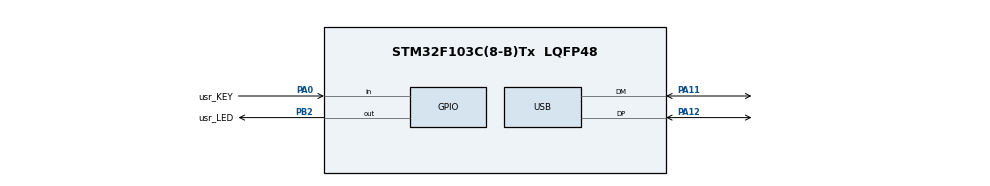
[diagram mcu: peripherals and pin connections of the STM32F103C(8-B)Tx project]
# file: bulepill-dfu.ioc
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Mcu.Family=STM32F1
Mcu.Name=STM32F103C(8-B)Tx
Mcu.Package=LQFP48
NVIC.PriorityGroup=NVIC_PRIORITYGROUP_4
NVIC.USB_LP_CAN1_RX0_IRQn=true\:0\:0\:false\:false\:true\:false\:true\:true
PA0-WKUP.GPIO_Label=usr_KEY
PA0-WKUP.GPIO_PuPd=GPIO_PULLDOWN
PA0-WKUP.Signal=GPIO_Input
PA11.Mode=Device
PA11.Signal=USB_DM
PA12.Mode=Device
PA12.Signal=USB_DP
PA13.Mode=Serial_Wire
PA13.Signal=SYS_JTMS-SWDIO
PA14.Mode=Serial_Wire
PA14.Signal=SYS_JTCK-SWCLK
PB2.GPIO_Label=usr_LED
PB2.Signal=GPIO_Output
PC14-OSC32_IN.Mode=LSE-External-Oscillator
PC14-OSC32_IN.Signal=RCC_OSC32_IN
PC15-OSC32_OUT.Mode=LSE-External-Oscillator
PC15-OSC32_OUT.Signal=RCC_OSC32_OUT
PD0-OSC_IN.Mode=HSE-External-Oscillator
PD0-OSC_IN.Signal=RCC_OSC_IN
PD1-OSC_OUT.Mode=HSE-External-Oscillator
PD1-OSC_OUT.Signal=RCC_OSC_OUT
ProjectManager.HeapSize=0x800
ProjectManager.StackSize=0x800
ProjectManager.TargetToolchain=Makefile
RCC.AHBFreq_Value=72000000
RCC.APB1CLKDivider=RCC_HCLK_DIV2
RCC.APB1Freq_Value=36000000
RCC.APB1TimFreq_Value=72000000
RCC.APB2Freq_Value=72000000
RCC.APB2TimFreq_Value=72000000
RCC.HCLKFreq_Value=72000000
RCC.HSICalibrationValue=8
RCC.PLLMUL=RCC_PLL_MUL9
RCC.SYSCLKFreq_VALUE=72000000
RCC.SYSCLKSource=RCC_SYSCLKSOURCE_PLLCLK
RCC.USBFreq_Value=48000000
RCC.USBPrescaler=RCC_USBCLKSOURCE_PLL_DIV1_5
USB_DEVICE.CLASS_NAME_FS=DFU
USB_DEVICE.USBD_DFU_APP_DEFAULT_ADD=0x08005800
USB_DEVICE.USBD_DFU_MEDIA=@Internal Flash   /0x08000000/22*001Ka,42*001Kg
USB_DEVICE.VirtualMode=Dfu
USB_DEVICE.VirtualModeFS=Dfu_FS
VP_USB_DEVICE_VS_USB_DEVICE_DFU_FS.Mode=DFU_FS
board=custom

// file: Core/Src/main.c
/* USER CODE BEGIN Header */
/**
  ******************************************************************************
  * @file           : main.c
  * @brief          : Main program body
  ******************************************************************************
  * @attention
  *
  * Copyright (c) 2024 STMicroelectronics.
  * All rights reserved.
  *
  * This software is licensed under terms that can be found in the LICENSE file
  * in the root directory of this software component.
  * If no LICENSE file comes with this software, it is provided AS-IS.
  *
  ******************************************************************************
  */
/* USER CODE END Header */
#include "main.h"
#include "usb_device.h"
#include "gpio.h"

/* USER CODE BEGIN PTD */
typedef  void (*pFunction)(void);
/* USER CODE END PTD */

void SystemClock_Config(void);
/* USER CODE BEGIN PFP */
void _close_r(void) {}
void _lseek_r(void) {}
void _read_r(void) {}
void _write_r(void) {}
/* USER CODE END PFP */

int main(void)
{
  /* USER CODE BEGIN 1 */
  pFunction JumpToApplication;
  uint32_t JumpAddress;
  /* USER CODE END 1 */

  /* MCU Configuration--------------------------------------------------------*/

  /* Reset of all peripherals, Initializes the Flash interface and the Systick. */
  HAL_Init();

  /* Configure the system clock */
  SystemClock_Config();

  /* Initialize all configured peripherals */
  MX_GPIO_Init();
  MX_USB_DEVICE_Init();
  /* USER CODE BEGIN 2 */
  // HAL_GPIO_ReadPin
  //LL_GPIO_IsInputPinSet
  if(HAL_GPIO_ReadPin(usr_KEY_GPIO_Port, usr_KEY_Pin) == GPIO_PIN_RESET)
    {
    /* Test if user code is programmed starting from address 0x08007000 */
        if (((*(__IO uint32_t *) USBD_DFU_APP_DEFAULT_ADD) & 0x2FFFB000) == 0x20000000)
        {
          /* Jump to user application */
          JumpAddress = *(__IO uint32_t *) (USBD_DFU_APP_DEFAULT_ADD + 4);
          JumpToApplication = (pFunction) JumpAddress;

          /* Initialize user application's Stack Pointer */
          __set_MSP(*(__IO uint32_t *) USBD_DFU_APP_DEFAULT_ADD);
          JumpToApplication();
        }
    }
  MX_USB_DEVICE_Init();

  /* USER CODE END 2 */

  /* Infinite loop */
  while (1)
  {

  }
}

void SystemClock_Config(void)
{
  LL_FLASH_SetLatency(LL_FLASH_LATENCY_2);
  while(LL_FLASH_GetLatency()!= LL_FLASH_LATENCY_2)
  {
  }
  LL_RCC_HSE_Enable();

   /* Wait till HSE is ready */
  while(LL_RCC_HSE_IsReady() != 1)
  {

  }
  LL_RCC_PLL_ConfigDomain_SYS(LL_RCC_PLLSOURCE_HSE_DIV_1, LL_RCC_PLL_MUL_9);
  LL_RCC_PLL_Enable();

   /* Wait till PLL is ready */
  while(LL_RCC_PLL_IsReady() != 1)
  {

  }
  LL_RCC_SetAHBPrescaler(LL_RCC_SYSCLK_DIV_1);
  LL_RCC_SetAPB1Prescaler(LL_RCC_APB1_DIV_2);
  LL_RCC_SetAPB2Prescaler(LL_RCC_APB2_DIV_1);
  LL_RCC_SetSysClkSource(LL_RCC_SYS_CLKSOURCE_PLL);

   /* Wait till System clock is ready */
  while(LL_RCC_GetSysClkSource() != LL_RCC_SYS_CLKSOURCE_STATUS_PLL)
  {

  }
  LL_SetSystemCoreClock(72000000);

   /* Update the time base */
  if (HAL_InitTick (TICK_INT_PRIORITY) != HAL_OK)
  {
    Error_Handler();
  }
  LL_RCC_SetUSBClockSource(LL_RCC_USB_CLKSOURCE_PLL_DIV_1_5);
}

void Error_Handler(void)
{
  __disable_irq();
  while (1)
  {
  }
}
